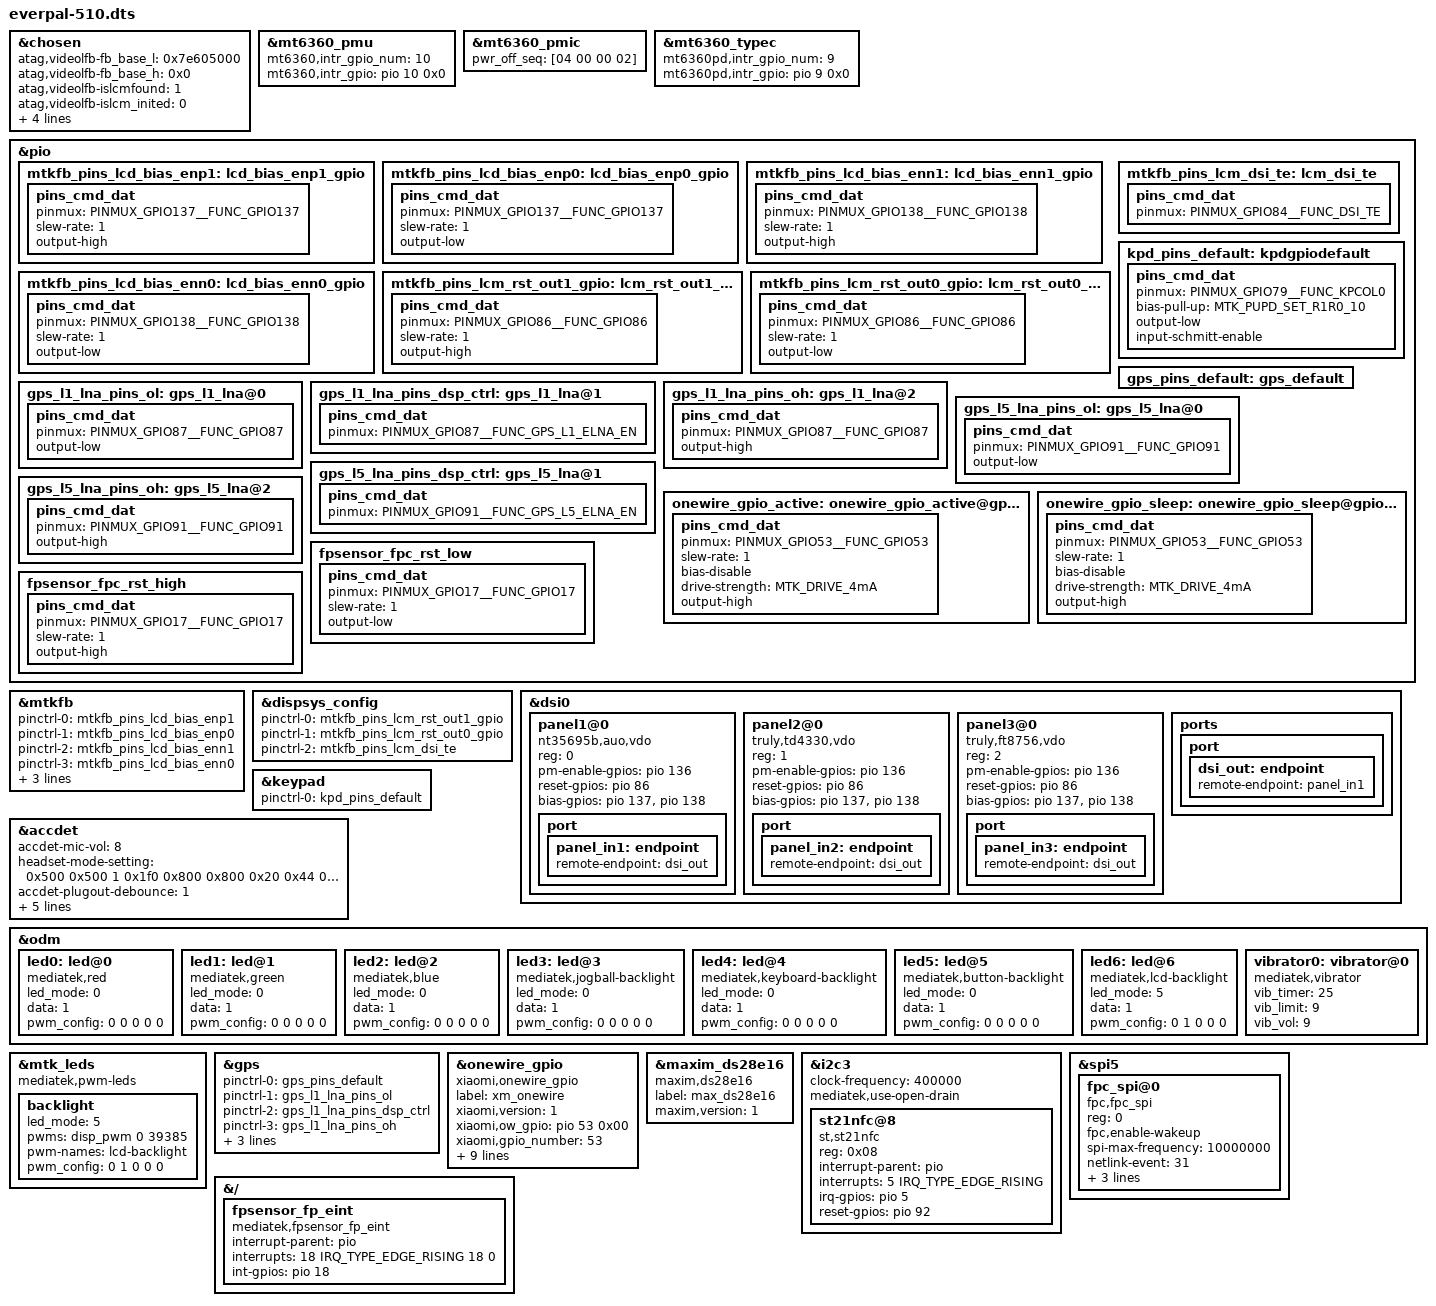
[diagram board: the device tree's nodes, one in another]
/* SPDX-License-Identifier: GPL-2.0 */
/*
 * everpal-510.dts — everpal (POCO M4 Pro 5G) board shell on 5.10 gold base.
 * Phase-1 shell ONLY: boots to console, no display/panel tuning, no
 * fingerprint/NFC/haptics/camera/touch bringup (later items).
 * Carried from 4.14 evergo.dts: &chosen block (verbatim), mt6360_typec
 * intr pio9. Display pinmux (137/138/86/84) verified identical both sides.
 * Gold panels/keypad/leds/gps/accdet/camera includes kept verbatim for
 * shell compile — each is a later port item. Vendor cust.dtsi stubbed.
 */
// SPDX-License-Identifier: GPL-2.0
/*
 * Copyright (c) 2019 MediaTek Inc.
 *
 */
/dts-v1/;
/plugin/;
#include <dt-bindings/interrupt-controller/irq.h>
#include <dt-bindings/interrupt-controller/arm-gic.h>
#include <dt-bindings/pinctrl/mt6833-pinfunc.h>

/* chosen */
&chosen {
	atag,videolfb-fb_base_l = <0x7e605000>;
	atag,videolfb-fb_base_h = <0x0>;
	atag,videolfb-islcmfound = <1>;
	atag,videolfb-islcm_inited = <0>;
	atag,videolfb-fps= <6000>;
	atag,videolfb-vramSize= <0x1be0000>;
	atag,videolfb-lcmname=
		"nt35595_fhd_dsi_cmd_truly_nt50358_drv";
};

&mt6360_pmu {
	mt6360,intr_gpio_num = <10>; /* direct defined GPIO num */
	mt6360,intr_gpio = <&pio 10 0x0>;
};

&mt6360_pmic {
	pwr_off_seq = [04 00 00 02];
};

&mt6360_typec {
	mt6360pd,intr_gpio_num = <9>; /* everpal: pio9 (gold uses pio11) */
	mt6360pd,intr_gpio = <&pio 9 0x0>;
};

&pio {
	mtkfb_pins_lcd_bias_enp1: lcd_bias_enp1_gpio {
		pins_cmd_dat {
			pinmux = <PINMUX_GPIO137__FUNC_GPIO137>;
			slew-rate = <1>;
			output-high;
		};
	};

	mtkfb_pins_lcd_bias_enp0: lcd_bias_enp0_gpio {
		pins_cmd_dat {
			pinmux = <PINMUX_GPIO137__FUNC_GPIO137>;
			slew-rate = <1>;
			output-low;
		};
	};

	mtkfb_pins_lcd_bias_enn1: lcd_bias_enn1_gpio {
		pins_cmd_dat {
			pinmux = <PINMUX_GPIO138__FUNC_GPIO138>;
			slew-rate = <1>;
			output-high;
		};
	};

	mtkfb_pins_lcd_bias_enn0: lcd_bias_enn0_gpio {
		pins_cmd_dat {
			pinmux = <PINMUX_GPIO138__FUNC_GPIO138>;
			slew-rate = <1>;
			output-low;
		};
	};

	mtkfb_pins_lcm_rst_out1_gpio: lcm_rst_out1_gpio {
		pins_cmd_dat {
			pinmux = <PINMUX_GPIO86__FUNC_GPIO86>;
			slew-rate = <1>;
			output-high;
		};
	};

	mtkfb_pins_lcm_rst_out0_gpio: lcm_rst_out0_gpio {
		pins_cmd_dat {
			pinmux = <PINMUX_GPIO86__FUNC_GPIO86>;
			slew-rate = <1>;
			output-low;
		};
	};
	mtkfb_pins_lcm_dsi_te: lcm_dsi_te {
		pins_cmd_dat {
			pinmux = <PINMUX_GPIO84__FUNC_DSI_TE>;
		};
	};
};

&mtkfb {
	pinctrl-names = "lcd_bias_enp1_gpio", "lcd_bias_enp0_gpio",
		"lcd_bias_enn1_gpio", "lcd_bias_enn0_gpio",
		"lcm_rst_out1_gpio", "lcm_rst_out0_gpio",
		"mode_te_te";
	pinctrl-0 = <&mtkfb_pins_lcd_bias_enp1>;
	pinctrl-1 = <&mtkfb_pins_lcd_bias_enp0>;
	pinctrl-2 = <&mtkfb_pins_lcd_bias_enn1>;
	pinctrl-3 = <&mtkfb_pins_lcd_bias_enn0>;
	pinctrl-4 = <&mtkfb_pins_lcm_rst_out1_gpio>;
	pinctrl-5 = <&mtkfb_pins_lcm_rst_out0_gpio>;
	pinctrl-6 = <&mtkfb_pins_lcm_dsi_te>;
	status = "okay";
};
&dispsys_config {
	pinctrl-names =
		"lcm_rst_out1_gpio", "lcm_rst_out0_gpio",
		"mode_te_te";
	pinctrl-0 = <&mtkfb_pins_lcm_rst_out1_gpio>;
	pinctrl-1 = <&mtkfb_pins_lcm_rst_out0_gpio>;
	pinctrl-2 = <&mtkfb_pins_lcm_dsi_te>;
	status = "okay";
};

&dsi0 {
	status = "okay";
	#address-cells = <1>;
	#size-cells = <0>;
	panel1@0 {
		compatible = "nt35695b,auo,vdo";
		reg = <0>;
		pm-enable-gpios = <&pio 136 0>;
		reset-gpios = <&pio 86 0>;
		bias-gpios = <&pio 137 0>,
			<&pio 138 0>;
		pinctrl-names = "default";
		port {
			panel_in1: endpoint {
				remote-endpoint = <&dsi_out>;
			};
		};
	};
	panel2@0 {
		compatible = "truly,td4330,vdo";
		reg = <1>;
		pm-enable-gpios = <&pio 136 0>;
		reset-gpios = <&pio 86 0>;
		bias-gpios = <&pio 137 0>,
			<&pio 138 0>;
		pinctrl-names = "default";
		port {
			panel_in2: endpoint {
				remote-endpoint = <&dsi_out>;
			};
		};
	};
	panel3@0 {
		compatible = "truly,ft8756,vdo";
		reg = <2>;
		pm-enable-gpios = <&pio 136 0>;
		reset-gpios = <&pio 86 0>;
		bias-gpios = <&pio 137 0>,
			<&pio 138 0>;
		pinctrl-names = "default";
		port {
			panel_in3: endpoint {
				remote-endpoint = <&dsi_out>;
			};
		};
	};
	ports {
		port {
			dsi_out: endpoint {
				remote-endpoint = <&panel_in1>;
			};
		};
	};
};

&keypad {
	pinctrl-names = "default";
	pinctrl-0 = <&kpd_pins_default>;
};

&pio {
	kpd_pins_default: kpdgpiodefault {
		pins_cmd_dat {
			pinmux = <PINMUX_GPIO79__FUNC_KPCOL0>;
			bias-pull-up = <MTK_PUPD_SET_R1R0_10>;
			output-low;
			input-schmitt-enable;
		};
	};
};


#include "mediatek/cust_mt6833_everpal_touch_nt36672c.dtsi" /* everpal NT36672C, see file header */
/* accdet start */
&accdet {
	/* accdet micbias voltage: 0x09:2.85v 0x08:2.8v 0x07,
	 * 2.7v;0x05,2.5v;0x02,1.9v
	 */
	accdet-mic-vol = <8>;
	/* accdet pwm_width, pwm_thresh, fall_delay, rise_delay
	 * debounce0, debounce1, debounce3, debounce4
	 * eint pwm_width, eint pwm_thresh
	 * eint deb(debounce0, debounce1, debounce2, debounce3), inv_debounce
	 */
	headset-mode-setting = <0x500 0x500 1 0x1f0
				0x800 0x800 0x20 0x44
				0x4 0x1
				0x5 0x3 0x3 0x5 0xe>;
	accdet-plugout-debounce = <1>;
	/*1:ACC mode, 2:low cost without in bias, 6:low cost with in bias*/
	accdet-mic-mode = <2>;
	/*0--MD_MAX--UP_MAX--DW_MAX*/
	headset-three-key-threshold = <0 80 220 400>;
	headset-three-key-threshold-CDD = <0 121 192 600>;
	/*0--MD_MAX--VOICE_MAX--UP_MAX--DW_MAX*/
	headset-four-key-threshold = <0 58 121 192 400>;

	/* select VTH to 2v and 500k, use internal resitance */
	eint_use_ext_res = <0>;
	status = "okay";
};
/* accdet end */

&odm {
	led0:led@0 {
		compatible = "mediatek,red";
		led_mode = <0>;
		data = <1>;
		pwm_config = <0 0 0 0 0>;
	};
	led1:led@1 {
		compatible = "mediatek,green";
		led_mode = <0>;
		data = <1>;
		pwm_config = <0 0 0 0 0>;
	};
	led2:led@2 {
		compatible = "mediatek,blue";
		led_mode = <0>;
		data = <1>;
		pwm_config = <0 0 0 0 0>;
	};
	led3:led@3 {
		compatible = "mediatek,jogball-backlight";
		led_mode = <0>;
		data = <1>;
		pwm_config = <0 0 0 0 0>;
	};
	led4:led@4 {
		compatible = "mediatek,keyboard-backlight";
		led_mode = <0>;
		data = <1>;
		pwm_config = <0 0 0 0 0>;
	};
	led5:led@5 {
		compatible = "mediatek,button-backlight";
		led_mode = <0>;
		data = <1>;
		pwm_config = <0 0 0 0 0>;
	};
	led6:led@6 {
		compatible = "mediatek,lcd-backlight";
		led_mode = <5>;
		data = <1>;
		pwm_config = <0 1 0 0 0>;
	};
	vibrator0:vibrator@0 {
		compatible = "mediatek,vibrator";
		vib_timer = <25>;
		vib_limit = <9>;
		vib_vol= <9>;
	};
};
&mtk_leds {
	compatible = "mediatek,pwm-leds";
	backlight {
		led_mode = <5>;
		pwms = <&disp_pwm 0 39385>;
		pwm-names = "lcd-backlight";
		pwm_config = <0 1 0 0 0>;
	};
};
/* GPS GPIO standardization start */
&pio {
	gps_pins_default: gps_default {
	};

	gps_l1_lna_pins_ol: gps_l1_lna@0 {
		pins_cmd_dat {
			pinmux = <PINMUX_GPIO87__FUNC_GPIO87>;
			output-low;
		};
	};
	gps_l1_lna_pins_dsp_ctrl: gps_l1_lna@1 {
		pins_cmd_dat {
			pinmux = <PINMUX_GPIO87__FUNC_GPS_L1_ELNA_EN>;
		};
	};
	gps_l1_lna_pins_oh: gps_l1_lna@2 {
		pins_cmd_dat {
			pinmux = <PINMUX_GPIO87__FUNC_GPIO87>;
			output-high;
		};
	};

	gps_l5_lna_pins_ol: gps_l5_lna@0 {
		pins_cmd_dat {
			pinmux = <PINMUX_GPIO91__FUNC_GPIO91>;
			output-low;
		};
	};
	gps_l5_lna_pins_dsp_ctrl: gps_l5_lna@1 {
		pins_cmd_dat {
			pinmux = <PINMUX_GPIO91__FUNC_GPS_L5_ELNA_EN>;
		};
	};
	gps_l5_lna_pins_oh: gps_l5_lna@2 {
		pins_cmd_dat {
			pinmux = <PINMUX_GPIO91__FUNC_GPIO91>;
			output-high;
		};
	};
};

&gps {
	pinctrl-names = "default",
		"gps_l1_lna_disable",
		"gps_l1_lna_dsp_ctrl",
		"gps_l1_lna_enable",
		"gps_l5_lna_disable",
		"gps_l5_lna_dsp_ctrl",
		"gps_l5_lna_enable";
	pinctrl-0 = <&gps_pins_default>;
	pinctrl-1 = <&gps_l1_lna_pins_ol>;
	pinctrl-2 = <&gps_l1_lna_pins_dsp_ctrl>;
	pinctrl-3 = <&gps_l1_lna_pins_oh>;
	pinctrl-4 = <&gps_l5_lna_pins_ol>;
	pinctrl-5 = <&gps_l5_lna_pins_dsp_ctrl>;
	pinctrl-6 = <&gps_l5_lna_pins_oh>;
	status = "okay";
};
/* GPS GPIO standardization end */
#include "mediatek/cust_mt6833_everpal_camera.dtsi" /* everpal sensors (ported drivers) */
#include <everpal-510/cust.dtsi> /* STUB, see everpal-510/cust.dtsi */



/* everpal battery auth (ported verbatim from 4.14 evergo.dts):
 * onewire bit-bang on GPIO53 + DS28E16 secure element.
 * Driver: drivers/misc/maxim/ (ported, CONFIG_BATT_VERIFY_BY_DS28E16).
 * NOTE: 5.10 gold uses GPIO19 + maxim,ds28e30 via auth_battery.dtsi —
 * NOT applicable to everpal hardware. */
&pio {
	/* default: GPIO53, output, high */
	onewire_gpio_active: onewire_gpio_active@gpio53 {
		pins_cmd_dat {
			pinmux = <PINMUX_GPIO53__FUNC_GPIO53>;
			slew-rate = <1>;
			bias-disable;
			drive-strength = <MTK_DRIVE_4mA>;
			output-high;
		};
	};

	onewire_gpio_sleep: onewire_gpio_sleep@gpio53 {
		pins_cmd_dat {
			pinmux = <PINMUX_GPIO53__FUNC_GPIO53>;
			slew-rate = <1>;
			bias-disable;
			drive-strength = <MTK_DRIVE_4mA>;
			output-high;
		};
	};
};

&onewire_gpio {
	compatible = "xiaomi,onewire_gpio";
	label = "xm_onewire";
	xiaomi,version = <1>;
	xiaomi,ow_gpio = <&pio 53 0x00>;
	xiaomi,gpio_number = <53>;//
	mi,onewire-gpio-dir-addr = <0x10005010>;//
	mi,onewire-gpio-dir-set-addr = <0x10005014>;//
	mi,onewire-gpio-dir-clr-addr = <0x10005018>;//
	mi,onewire-gpio-dout-addr = <0x10005110>;//
	mi,onewire-gpio-dout-set-addr = <0x10005114>;//
	mi,onewire-gpio-dout-clr-addr = <0x10005118>;//
	mi,onewire-gpio-din-addr = <0x10005210>;//
	pinctrl-names = "onewire_active", "onewire_sleep";
	pinctrl-0 = <&onewire_gpio_active>;
	pinctrl-1 = <&onewire_gpio_sleep>;
	status = "okay";
};

&maxim_ds28e16 {
	compatible = "maxim,ds28e16";
	label = "max_ds28e16";
	maxim,version = <1>;
	status = "okay";
};


/* everpal NFC (adapted from 4.14 evergo.dts i2c3/st21nfc@8):
 * 5.10 driver (drivers/misc/mediatek/nfc/st21nfc) binds "st,st21nfc"
 * with irq-gpios/reset-gpios + client->irq — NOT 4.14's
 * "mediatek,nfc-gpio-v2" bare-number style. Same bus (i2c3@400kHz),
 * same address (0x08), same GPIOs (RST pio92, IRQ pio5 edge-rising). */
&i2c3 {
	clock-frequency = <400000>;
	mediatek,use-open-drain;
	status = "okay";

	st21nfc@8 {
		compatible = "st,st21nfc";
		reg = <0x08>;
		interrupt-parent = <&pio>;
		interrupts = <5 IRQ_TYPE_EDGE_RISING>;
		irq-gpios = <&pio 5 0>;
		reset-gpios = <&pio 92 0>;
		status = "okay";
	};
};


/* everpal fingerprint (ported from 4.14 evergo.dts):
 * FPC1542 on spi5 (10MHz, RST pio17, wakeup, netlink 31, vfp-supply)
 * + Goodix-compat EINT on pio18 (dual footprint, FPC populated).
 * Driver: drivers/input/fingerprint/fpc1542/mtk_spi.c (ported). */
&pio {
	fpsensor_fpc_rst_low: fpsensor_fpc_rst_low {
		pins_cmd_dat {
			pinmux = <PINMUX_GPIO17__FUNC_GPIO17>;
			slew-rate = <1>;
			output-low;
		};
	};

	fpsensor_fpc_rst_high: fpsensor_fpc_rst_high {
		pins_cmd_dat {
			pinmux = <PINMUX_GPIO17__FUNC_GPIO17>;
			slew-rate = <1>;
			output-high;
		};
	};
};

&spi5 {
	fpc_spi@0 {
		compatible = "fpc,fpc_spi";
		reg = <0>;
		fpc,enable-wakeup;
		spi-max-frequency = <10000000>;
		netlink-event = <31>;
		vfp-supply = <&mt_pmic_vfp_ldo_reg>;
		pinctrl-names = "fpsensor_fpc_rst_low", "fpsensor_fpc_rst_high";
		pinctrl-0 = <&fpsensor_fpc_rst_low>;
		pinctrl-1 = <&fpsensor_fpc_rst_high>;
		status = "okay";
	};
};

/* 5.10 base lacks the fpsensor_fp_eint stub that 4.14 mt6833.dts provides.
 * Added as a child of root via &{/} override (explicit fragment@N blocks
 * are rejected by the toolchain dtc). The driver finds it by compatible
 * anywhere in the tree. */
&{/} {
	fpsensor_fp_eint: fpsensor_fp_eint {
		compatible = "mediatek,fpsensor_fp_eint";
		interrupt-parent = <&pio>;
		interrupts = <18 IRQ_TYPE_EDGE_RISING 18 0>;
		int-gpios = <&pio 18 0>;
		status = "okay";
	};
};

/*End of this file, DO NOT ADD ANYTHING HERE*/
